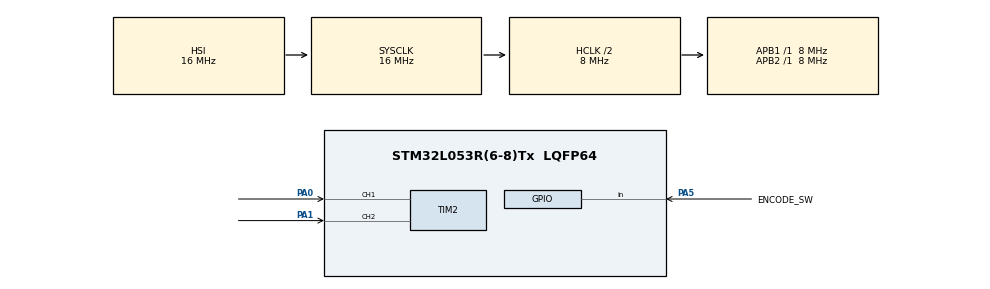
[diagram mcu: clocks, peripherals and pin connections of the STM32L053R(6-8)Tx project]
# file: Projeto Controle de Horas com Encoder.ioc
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Mcu.Family=STM32L0
Mcu.Name=STM32L053R(6-8)Tx
Mcu.Package=LQFP64
PA0.Signal=S_TIM2_CH1
PA1.Signal=S_TIM2_CH2
PA5.GPIO_Label=ENCODE_SW
PA5.GPIO_PuPd=GPIO_PULLUP
PA5.Signal=GPIO_Input
ProjectManager.HeapSize=0x200
ProjectManager.StackSize=0x400
ProjectManager.TargetToolchain=STM32CubeIDE
RCC.AHBCLKDivider=RCC_SYSCLK_DIV2
RCC.AHBFreq_Value=8000000
RCC.APB1Freq_Value=8000000
RCC.APB1TimFreq_Value=8000000
RCC.APB2Freq_Value=8000000
RCC.APB2TimFreq_Value=8000000
RCC.HCLKFreq_Value=8000000
RCC.HSE_VALUE=8000000
RCC.HSI16_VALUE=16000000
RCC.HSI48_VALUE=48000000
RCC.HSI_VALUE=16000000
RCC.LSE_VALUE=32768
RCC.MSI_VALUE=2097000
RCC.SYSCLKFreq_VALUE=16000000
RCC.SYSCLKSource=RCC_SYSCLKSOURCE_HSI
RCC.VCOOutputFreq_Value=48000000
SH.S_TIM2_CH1.0=TIM2_CH1,Encoder_Interface
SH.S_TIM2_CH2.0=TIM2_CH2,Encoder_Interface
TIM2.EncoderMode=TIM_ENCODERMODE_TI12
TIM2.IC1Filter=10
VP_RTC_VS_RTC_Activate.Mode=RTC_Enabled
VP_RTC_VS_RTC_Calendar.Mode=RTC_Calendar
board=NUCLEO-L053R8

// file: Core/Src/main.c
/* USER CODE BEGIN Header */
/**
  ******************************************************************************
  * @file           : main.c
  * @brief          : Main program body
  ******************************************************************************
  * @attention
  *
  * Copyright (c) 2025 STMicroelectronics.
  * All rights reserved.
  *
  * This software is licensed under terms that can be found in the LICENSE file
  * in the root directory of this software component.
  * If no LICENSE file comes with this software, it is provided AS-IS.
  *
  ******************************************************************************
  */
/* USER CODE END Header */
#include "main.h"

RTC_HandleTypeDef hrtc;

TIM_HandleTypeDef htim2;

/* USER CODE BEGIN PV */
int16_t ATUAL_TICK, LAST_TICK, CONTROL_DIR;
int32_t ATUAL_TIME, LAST_TIME, CONTROL_WAS_PRESS, CONTROL_PRESS;

uint8_t ATUAL_MENU, DOUBLE_CLICK, LARGE_PRESS, SHORT_PRESS, OP;
uint8_t minutes, seconds, hours, day, month, year;
RTC_TimeTypeDef TIME;
RTC_DateTypeDef DATE;
/* USER CODE END PV */

void SystemClock_Config(void);
static void MX_GPIO_Init(void);
static void MX_TIM2_Init(void);
static void MX_RTC_Init(void);
/* USER CODE BEGIN PFP */
void SET_TIME(void);
void MENU_CONTROL(void);
void ENCODER_VERIFY(void);
void KEYBOARD_CHECK(GPIO_TypeDef *GPIOx, uint16_t GPIO_Pin);

/* USER CODE END PFP */

int main(void)
{

  /* MCU Configuration--------------------------------------------------------*/

  /* Reset of all peripherals, Initializes the Flash interface and the Systick. */
  HAL_Init();

  /* Configure the system clock */
  SystemClock_Config();

  /* Initialize all configured peripherals */
  MX_GPIO_Init();
  MX_TIM2_Init();
  MX_RTC_Init();
  /* USER CODE BEGIN 2 */

  DATE.Date  = 28;
  DATE.Month = 7;
  DATE.Year  = 25;
  DATE.WeekDay = RTC_WEEKDAY_MONDAY;

  TIME.Hours = 16;
  TIME.Minutes = 15;

  HAL_TIM_Encoder_Start(&htim2, TIM_CHANNEL_ALL);
  SET_TIME();

  /* USER CODE END 2 */

  /* Infinite loop */
  /* USER CODE BEGIN WHILE */
  while (1) {

	  MENU_CONTROL();

    /* USER CODE END WHILE */

  }
}

void SystemClock_Config(void)
{
  RCC_OscInitTypeDef RCC_OscInitStruct = {0};
  RCC_ClkInitTypeDef RCC_ClkInitStruct = {0};
  RCC_PeriphCLKInitTypeDef PeriphClkInit = {0};

  /** Configure the main internal regulator output voltage
  */
  __HAL_PWR_VOLTAGESCALING_CONFIG(PWR_REGULATOR_VOLTAGE_SCALE1);

  /** Initializes the RCC Oscillators according to the specified parameters
  * in the RCC_OscInitTypeDef structure.
  */
  RCC_OscInitStruct.OscillatorType = RCC_OSCILLATORTYPE_HSI|RCC_OSCILLATORTYPE_LSI;
  RCC_OscInitStruct.HSIState = RCC_HSI_ON;
  RCC_OscInitStruct.HSICalibrationValue = RCC_HSICALIBRATION_DEFAULT;
  RCC_OscInitStruct.LSIState = RCC_LSI_ON;
  RCC_OscInitStruct.PLL.PLLState = RCC_PLL_NONE;
  if (HAL_RCC_OscConfig(&RCC_OscInitStruct) != HAL_OK)
  {
    Error_Handler();
  }

  /** Initializes the CPU, AHB and APB buses clocks
  */
  RCC_ClkInitStruct.ClockType = RCC_CLOCKTYPE_HCLK|RCC_CLOCKTYPE_SYSCLK
                              |RCC_CLOCKTYPE_PCLK1|RCC_CLOCKTYPE_PCLK2;
  RCC_ClkInitStruct.SYSCLKSource = RCC_SYSCLKSOURCE_HSI;
  RCC_ClkInitStruct.AHBCLKDivider = RCC_SYSCLK_DIV2;
  RCC_ClkInitStruct.APB1CLKDivider = RCC_HCLK_DIV1;
  RCC_ClkInitStruct.APB2CLKDivider = RCC_HCLK_DIV1;

  if (HAL_RCC_ClockConfig(&RCC_ClkInitStruct, FLASH_LATENCY_0) != HAL_OK)
  {
    Error_Handler();
  }
  PeriphClkInit.PeriphClockSelection = RCC_PERIPHCLK_RTC;
  PeriphClkInit.RTCClockSelection = RCC_RTCCLKSOURCE_LSI;
  if (HAL_RCCEx_PeriphCLKConfig(&PeriphClkInit) != HAL_OK)
  {
    Error_Handler();
  }
}

static void MX_RTC_Init(void)
{

  RTC_TimeTypeDef sTime = {0};
  RTC_DateTypeDef sDate = {0};

  /** Initialize RTC Only
  */
  hrtc.Instance = RTC;
  hrtc.Init.HourFormat = RTC_HOURFORMAT_24;
  hrtc.Init.AsynchPrediv = 127;
  hrtc.Init.SynchPrediv = 255;
  hrtc.Init.OutPut = RTC_OUTPUT_DISABLE;
  hrtc.Init.OutPutRemap = RTC_OUTPUT_REMAP_NONE;
  hrtc.Init.OutPutPolarity = RTC_OUTPUT_POLARITY_HIGH;
  hrtc.Init.OutPutType = RTC_OUTPUT_TYPE_OPENDRAIN;
  if (HAL_RTC_Init(&hrtc) != HAL_OK)
  {
    Error_Handler();
  }

  /** Initialize RTC and set the Time and Date
  */
  sTime.Hours = 0x0;
  sTime.Minutes = 0x0;
  sTime.Seconds = 0x0;
  sTime.DayLightSaving = RTC_DAYLIGHTSAVING_NONE;
  sTime.StoreOperation = RTC_STOREOPERATION_RESET;
  if (HAL_RTC_SetTime(&hrtc, &sTime, RTC_FORMAT_BCD) != HAL_OK)
  {
    Error_Handler();
  }
  sDate.WeekDay = RTC_WEEKDAY_MONDAY;
  sDate.Month = RTC_MONTH_JANUARY;
  sDate.Date = 0x1;
  sDate.Year = 0x0;

  if (HAL_RTC_SetDate(&hrtc, &sDate, RTC_FORMAT_BCD) != HAL_OK)
  {
    Error_Handler();
  }

}

static void MX_TIM2_Init(void)
{

  TIM_Encoder_InitTypeDef sConfig = {0};
  TIM_MasterConfigTypeDef sMasterConfig = {0};

  htim2.Instance = TIM2;
  htim2.Init.Prescaler = 0;
  htim2.Init.CounterMode = TIM_COUNTERMODE_UP;
  htim2.Init.Period = 65535;
  htim2.Init.ClockDivision = TIM_CLOCKDIVISION_DIV1;
  htim2.Init.AutoReloadPreload = TIM_AUTORELOAD_PRELOAD_DISABLE;
  sConfig.EncoderMode = TIM_ENCODERMODE_TI12;
  sConfig.IC1Polarity = TIM_ICPOLARITY_RISING;
  sConfig.IC1Selection = TIM_ICSELECTION_DIRECTTI;
  sConfig.IC1Prescaler = TIM_ICPSC_DIV1;
  sConfig.IC1Filter = 10;
  sConfig.IC2Polarity = TIM_ICPOLARITY_RISING;
  sConfig.IC2Selection = TIM_ICSELECTION_DIRECTTI;
  sConfig.IC2Prescaler = TIM_ICPSC_DIV1;
  sConfig.IC2Filter = 0;
  if (HAL_TIM_Encoder_Init(&htim2, &sConfig) != HAL_OK)
  {
    Error_Handler();
  }
  sMasterConfig.MasterOutputTrigger = TIM_TRGO_RESET;
  sMasterConfig.MasterSlaveMode = TIM_MASTERSLAVEMODE_DISABLE;
  if (HAL_TIMEx_MasterConfigSynchronization(&htim2, &sMasterConfig) != HAL_OK)
  {
    Error_Handler();
  }

}

static void MX_GPIO_Init(void)
{
  GPIO_InitTypeDef GPIO_InitStruct = {0};

  /* GPIO Ports Clock Enable */
  __HAL_RCC_GPIOA_CLK_ENABLE();

  /*Configure GPIO pin : ENCODE_SW_Pin */
  GPIO_InitStruct.Pin = ENCODE_SW_Pin;
  GPIO_InitStruct.Mode = GPIO_MODE_INPUT;
  GPIO_InitStruct.Pull = GPIO_PULLUP;
  HAL_GPIO_Init(ENCODE_SW_GPIO_Port, &GPIO_InitStruct);

}

/* USER CODE BEGIN 4 */
void SET_TIME(void){
	HAL_RTC_SetDate(&hrtc, &DATE, RTC_FORMAT_BCD);
	HAL_RTC_SetTime(&hrtc, &TIME, RTC_FORMAT_BCD);
}

void ENCODER_VERIFY(void){
	int16_t DELTA = (int16_t)(TIM2->CNT - LAST_TICK);

	if(DELTA > 0) CONTROL_DIR = -1;
	else if (DELTA < 0) CONTROL_DIR  = 1;
	else CONTROL_DIR = 0;

	LAST_TICK = TIM2->CNT;
}

void KEYBOARD_CHECK(GPIO_TypeDef *GPIOx, uint16_t GPIO_Pin){
	uint8_t press = !HAL_GPIO_ReadPin(GPIOx, GPIO_Pin);
	uint32_t now_time = HAL_GetTick();

	// Verificar se foi precionado
	if(press && !CONTROL_WAS_PRESS){
		if(now_time - LAST_TIME < 500) CONTROL_PRESS++;
		else CONTROL_PRESS = 1;

		LAST_TIME = now_time;
	}

	// Clique duplo
	if(CONTROL_PRESS == 2 && (now_time - LAST_TIME > 500)) DOUBLE_CLICK = 1;

	// Clique longo
	if(!press && CONTROL_WAS_PRESS){
		uint32_t press_duration = now_time - LAST_TIME;

		if(press_duration >= 3000 && press_duration <= 5000) LARGE_PRESS = 1;
		else LARGE_PRESS = 0;
	}

	// Clique curto
	CONTROL_WAS_PRESS = press;
}

void MENU_CONTROL(void){
	KEYBOARD_CHECK(ENCODE_SW_GPIO_Port, ENCODE_SW_Pin);

	switch(ATUAL_MENU){
		case 1:
			HAL_RTC_GetDate(&hrtc, &DATE, RTC_FORMAT_BCD);
			HAL_RTC_GetTime(&hrtc, &TIME, RTC_FORMAT_BCD);

			if(DOUBLE_CLICK) {
				CONTROL_PRESS = 0;
				DOUBLE_CLICK = 0;
				ATUAL_MENU = 2;
			}

			if(LARGE_PRESS) {
				CONTROL_PRESS = 0;
				LARGE_PRESS = 0;
				ATUAL_MENU = 3;
			}
			break;

		case 2:
			ENCODER_VERIFY();

			if(CONTROL_WAS_PRESS) {
				// Delay para incremento
				HAL_Delay(100);
				OP++;
			}

			switch(OP){
				case 0:
					hours += CONTROL_DIR;
					break;

				case 1:
					minutes += CONTROL_DIR;
					break;

				case 2:
					seconds += CONTROL_DIR;
					break;

				default:
					OP = 0;
			}

			if(DOUBLE_CLICK) {
				CONTROL_PRESS = 0;
				DOUBLE_CLICK = 0;
				ATUAL_MENU = 1;

				TIME.Hours = hours;
				TIME.Seconds = seconds;
				TIME.Minutes = minutes;

				SET_TIME();
			}

			// Delay para o Encoder
			HAL_Delay(100);
			break;

		case 3:
			break;

		default:
			ATUAL_MENU = 1;
			break;
	}
}

/* USER CODE END 4 */

void Error_Handler(void)
{
  __disable_irq();
  while (1)
  {
  }
}
